# STM32U031 register map
File version: 1.0
CPU: CM0+ r0p1, little endian, MPU, no FPU, 4 interrupt priority bits
Registers are 32-bit, read-write, reset 0x0 unless marked. A register's access mark holds for its fields unless they carry their own. Offsets are from the block's base; [hi:lo] are bit positions; {n}, {i} and the like mark numbered series.

## EXTI — EXTI register block
Base 0x40021800
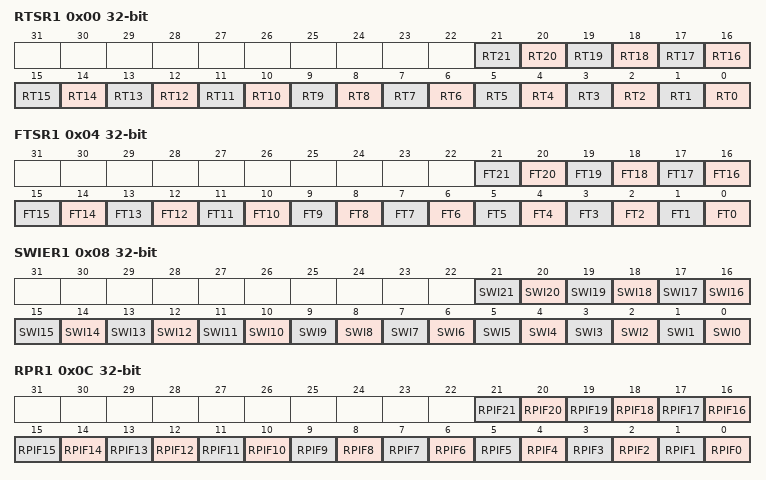
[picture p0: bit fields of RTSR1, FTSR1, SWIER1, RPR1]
0x00 RTSR1 — EXTI rising trigger selection register
  [n] RT{n} (n=0..21) — Rising trigger event configuration bit of configurable line x (x1=1211to10) Each bit enables/disables the rising edge trigger for the event and interrupt on the corresponding line. Bits 18 and 19 are available only on STM32U0x3xx devices. They are reserved on STM32U031xx devices.
0x04 FTSR1 — EXTI falling trigger selection register 1
  [n] FT{n} (n=0..21) — Falling trigger event configuration bit of configurable line x (x1=1211to10) Each bit enables/disables the falling edge trigger for the event and interrupt on the corresponding line. Bits 18 and 19 are available only on STM32U0x3xx devices. They are reserved on STM32U031xx devices.
0x08 SWIER1 — EXTI software interrupt event register 1
  [n] SWI{n} (n=0..21) — Software rising edge event trigger on line x (x1=1211to10) Setting of any bit by software triggers a rising edge event on the corresponding line x, resulting in an interrupt, independently of EXTI_RTSR1 and EXTI_FTSR1 settings. The bits are automatically cleared by HW. Reading of any bit always returns 0. Bits 18 and 19 are available only on STM32U0x3xx devices. They are reserved on STM32U031xx devices.
0x0C RPR1 — EXTI rising edge pending register 1
  [n] RPIF{n} (n=0..21) — Rising edge event pending for configurable line x (x1=1211to10) Each bit is set upon a rising edge event generated by hardware or by software (through the EXTI_SWIER1 register) on the corresponding line. Each bit is cleared by writing 1 into it. Bits 18 and 19 are available only on STM32U0x3xx devices. They are reserved on STM32U031xx devices.
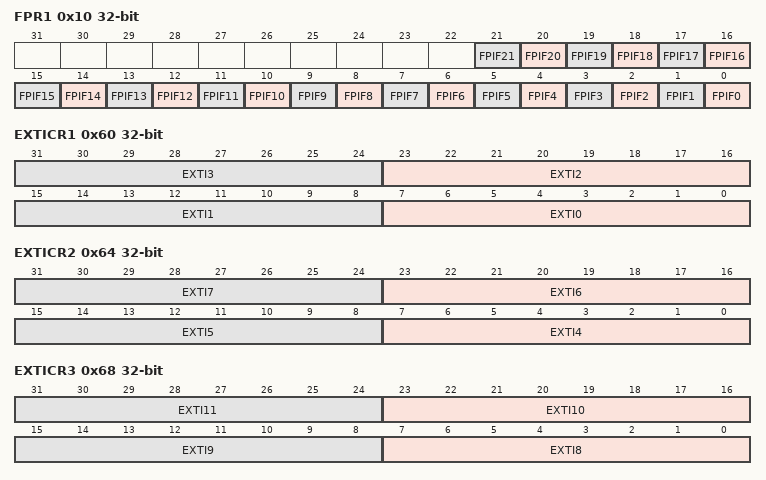
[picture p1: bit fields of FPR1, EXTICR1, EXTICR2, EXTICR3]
0x10 FPR1 — EXTI falling edge pending register 1
  [n] FPIF{n} (n=0..21) — Falling edge event pending for configurable line x (x1=1211to10) Each bit is set upon a falling edge event generated by hardware or by software (through the EXTI_SWIER1 register) on the corresponding line. Each bit is cleared by writing 1 into it. Bits 18 and 19 are available only on STM32U0x3xx devices. They are reserved on STM32U031xx devices.
0x60 EXTICR1 — EXTI external interrupt selection register 1
  [8n+7:8n] EXTI{n} (n=0..3) — EXTI{n} GPIO port selection These bits are written by software to select the source input for EXTI{n} external interrupt. Others reserved
0x64 EXTICR2 — EXTI external interrupt selection register 2
  [8n-25:8n-32] EXTI{n} (n=4..7) — EXTI{n} GPIO port selection These bits are written by software to select the source input for EXTI{n} external interrupt. Others reserved
0x68 EXTICR3 — EXTI external interrupt selection register 3
  [8n-57:8n-64] EXTI{n} (n=8..11) — EXTI{n} GPIO port selection These bits are written by software to select the source input for EXTI{n} external interrupt. Others reserved
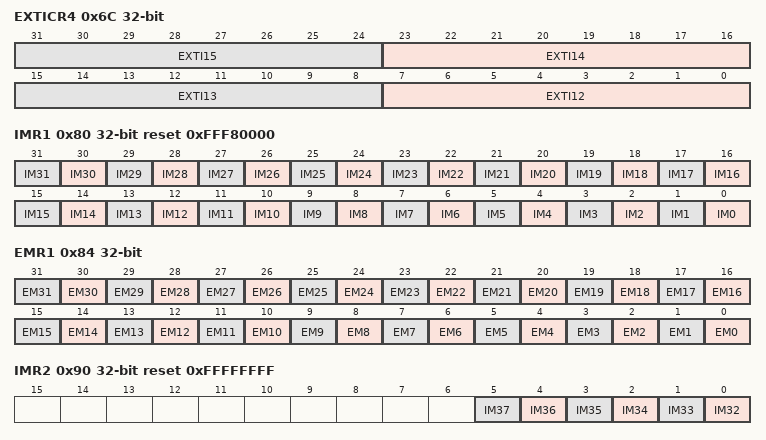
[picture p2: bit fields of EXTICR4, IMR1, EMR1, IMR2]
0x6C EXTICR4 — EXTI external interrupt selection register 4
  [8n-89:8n-96] EXTI{n} (n=12..15) — EXTI{n} GPIO port selection These bits are written by software to select the source input for EXTI{n} external interrupt. Others reserved
0x80 IMR1 reset 0xFFF80000 — EXTI CPU wake-up with interrupt mask register
  [n] IM{n} (n=0..31) — CPU wake-up with interrupt mask on line x (x1=131 to 0) Setting/clearing each bit unmasks/masks the CPU wake-up with interrupt, by an event on the corresponding line. Bits 18, 19, 22 and 26 are available only on STM32U0x3xx devices, they are reserved on STM32U031xx devices.
0x84 EMR1 — EXTI CPU wake-up with event mask register
  [n] EM{n} (n=0..31) — CPU wake-up with event generation mask on line x (x1=1311to10) Setting/clearing each bit unmasks/masks the CPU wake-up with event generation on the corresponding line. Bits 18, 19, 22 and 26 are available only on STM32U0x3xx devices, they are reserved on STM32U031xx devices.
0x90 IMR2 reset 0xFFFFFFFF — EXTI CPU wake-up with interrupt mask register
  [n-32] IM{n} (n=32..37) — CPU wake-up with interrupt mask on line x (x1=1371to132) Setting/clearing this bit unmasks/masks the CPU wake-up with interrupt, by an event on the corresponding line. Bit IM36 is available only on STM32U0x3xx devices, it is reserved on STM32U031xx devices.
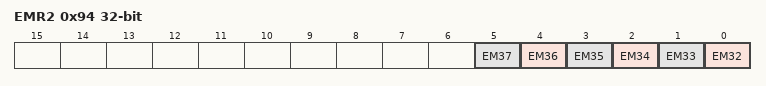
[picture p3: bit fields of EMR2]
0x94 EMR2 — EXTI CPU wake-up with event mask register
  [n-32] EM{n} (n=32..37) — CPU wake-up with event generation mask on line x, (x1=1371to132) Setting/clearing each bit unmasks/masks the CPU wake-up with event generation on the corresponding line. Bit IM36 is available only on STM32U0x3xx devices, it is reserved on STM32U031xx devices.
